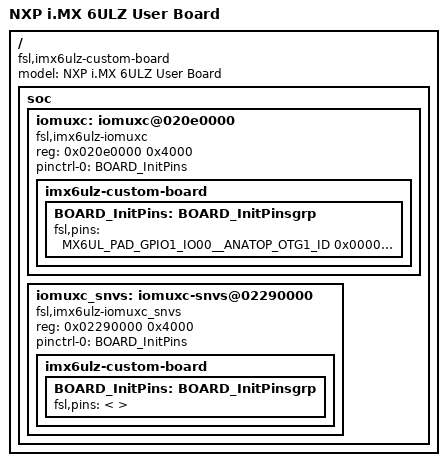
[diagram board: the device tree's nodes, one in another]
/***********************************************************************************************************************
 * This file was generated by the MCUXpresso Config Tools. Any manual edits made to this file
 * will be overwritten if the respective MCUXpresso Config Tools is used to update this file.
 **********************************************************************************************************************/

/*
 * TEXT BELOW IS USED AS SETTING FOR TOOLS *************************************
!!GlobalInfo
product: Pins v8.0
processor: MCIMX6Z0xxx09
package_id: MCIMX6Z0DVM09
mcu_data: ksdk2_0
processor_version: 8.0.0
 * BE CAREFUL MODIFYING THIS COMMENT - IT IS YAML SETTINGS FOR TOOLS ***********
 */


/dts-v1/;

#include "skeleton.dtsi"
#include "imx6ull-pinfunc.h"

/ {
    model = "NXP i.MX 6ULZ User Board";
    compatible = "fsl,imx6ulz-custom-board", "fsl,imx6ulz";

    soc {
        #address-cells = <1>;
        #size-cells = <1>;

        iomuxc: iomuxc@020e0000 {
            compatible = "fsl,imx6ulz-iomuxc";
            reg = <0x020e0000 0x4000>;
        };

        iomuxc_snvs: iomuxc-snvs@02290000 {
            compatible = "fsl,imx6ulz-iomuxc_snvs";
            reg = <0x02290000 0x4000>;
        };
    };
};

&iomuxc {
    pinctrl-names = "default_iomuxc";
    pinctrl-0 = <&BOARD_InitPins>;


    imx6ulz-custom-board {
        BOARD_InitPins: BOARD_InitPinsgrp {                /*!< Function assigned for the core: Cortex-A7[ca7] */
/*
 * TEXT BELOW IS USED AS SETTING FOR TOOLS *************************************
BOARD_InitPins:
- options: {callFromInitBoot: 'false', coreID: ca7}
- pin_list:
  - {pin_num: B3, peripheral: USDHC1, signal: 'usdhc_data, 0', pin_signal: SD1_DATA0}
  - {pin_num: B2, peripheral: USDHC1, signal: 'usdhc_data, 1', pin_signal: SD1_DATA1}
  - {pin_num: B1, peripheral: USDHC1, signal: 'usdhc_data, 2', pin_signal: SD1_DATA2}
  - {pin_num: A2, peripheral: USDHC1, signal: 'usdhc_data, 3', pin_signal: SD1_DATA3}
  - {pin_num: C2, peripheral: USDHC1, signal: usdhc_cmd, pin_signal: SD1_CMD}
  - {pin_num: C1, peripheral: USDHC1, signal: usdhc_clk, pin_signal: SD1_CLK}
  - {pin_num: J14, peripheral: USDHC1, signal: usdhc_cd_b, pin_signal: UART1_RTS_B}
  - {pin_num: D8, peripheral: USDHC2, signal: usdhc_clk, pin_signal: NAND_RE_B}
  - {pin_num: C8, peripheral: USDHC2, signal: usdhc_cmd, pin_signal: NAND_WE_B}
  - {pin_num: B7, peripheral: USDHC2, signal: 'usdhc_data, 1', pin_signal: NAND_DATA01}
  - {pin_num: D7, peripheral: USDHC2, signal: 'usdhc_data, 0', pin_signal: NAND_DATA00}
  - {pin_num: A7, peripheral: USDHC2, signal: 'usdhc_data, 2', pin_signal: NAND_DATA02}
  - {pin_num: D6, peripheral: USDHC2, signal: 'usdhc_data, 3', pin_signal: NAND_DATA03}
  - {pin_num: K14, peripheral: UART1, signal: uart_tx, pin_signal: UART1_TX_DATA}
  - {pin_num: K16, peripheral: UART1, signal: uart_rx, pin_signal: UART1_RX_DATA}
  - {pin_num: J17, peripheral: UART2, signal: uart_tx, pin_signal: UART2_TX_DATA}
  - {pin_num: J16, peripheral: UART2, signal: uart_rx, pin_signal: UART2_RX_DATA}
  - {pin_num: H14, peripheral: UART2, signal: uart_rts_b, pin_signal: UART2_RTS_B}
  - {pin_num: J15, peripheral: UART2, signal: uart_cts_b, pin_signal: UART2_CTS_B}
  - {pin_num: N17, peripheral: PWM1, signal: pwm_out, pin_signal: GPIO1_IO08}
  - {pin_num: M15, peripheral: PWM2, signal: pwm_out, pin_signal: GPIO1_IO09}
  - {pin_num: M16, peripheral: PWM3, signal: pwm_out, pin_signal: GPIO1_IO04}
  - {pin_num: M17, peripheral: PWM4, signal: pwm_out, pin_signal: GPIO1_IO05}
  - {pin_num: G17, peripheral: I2C1, signal: i2c_scl, pin_signal: UART4_TX_DATA}
  - {pin_num: G16, peripheral: I2C1, signal: i2c_sda, pin_signal: UART4_RX_DATA}
  - {pin_num: E1, peripheral: SAI1, signal: sai_rx_bclk, pin_signal: SD2_DATA03}
  - {pin_num: E3, peripheral: SAI1, signal: sai_mclk, pin_signal: SD2_DATA01}
  - {pin_num: D2, peripheral: SAI1, signal: sai_rx_data, pin_signal: SD2_DATA06}
  - {pin_num: E2, peripheral: SAI1, signal: sai_rx_sync, pin_signal: SD2_DATA02}
  - {pin_num: D3, peripheral: SAI1, signal: sai_tx_bclk, pin_signal: SD2_DATA05}
  - {pin_num: D1, peripheral: SAI1, signal: sai_tx_data, pin_signal: SD2_DATA07}
  - {pin_num: D4, peripheral: SAI1, signal: sai_tx_sync, pin_signal: SD2_DATA04}
  - {pin_num: K13, peripheral: USB, signal: usb_otg1_id, pin_signal: GPIO1_IO00}
  - {pin_num: D17, peripheral: USB, signal: usb_otg2_id, pin_signal: KPP_ROW7}
  - {pin_num: E6, peripheral: QSPI, signal: qspi_a_ss0_b, pin_signal: NAND_DQS}
  - {pin_num: A5, peripheral: QSPI, signal: qspi_a_ss1_b, pin_signal: NAND_DATA07}
  - {pin_num: D5, peripheral: QSPI, signal: qspi_a_sclk, pin_signal: NAND_WP_B}
  - {pin_num: A3, peripheral: QSPI, signal: 'qspi_a_data, 0', pin_signal: NAND_READY_B}
  - {pin_num: C5, peripheral: QSPI, signal: 'qspi_a_data, 1', pin_signal: NAND_CE0_B}
  - {pin_num: B5, peripheral: QSPI, signal: 'qspi_a_data, 2', pin_signal: NAND_CE1_B}
  - {pin_num: A4, peripheral: QSPI, signal: 'qspi_a_data, 3', pin_signal: NAND_CLE}
  - {pin_num: B4, peripheral: QSPI, signal: qspi_a_dqs, pin_signal: NAND_ALE}
  - {pin_num: H16, peripheral: UART3, signal: uart_rx, pin_signal: UART3_RX_DATA}
  - {pin_num: H17, peripheral: UART3, signal: uart_tx, pin_signal: UART3_TX_DATA}
  - {pin_num: G14, peripheral: UART3, signal: uart_rts_b, pin_signal: UART3_RTS_B}
  - {pin_num: H15, peripheral: UART3, signal: uart_cts_b, pin_signal: UART3_CTS_B}
  - {pin_num: M15, peripheral: SPDIF, signal: spdif_in, pin_signal: GPIO1_IO09}
  - {pin_num: N17, peripheral: SPDIF, signal: spdif_out, pin_signal: GPIO1_IO08}
  - {pin_num: F17, peripheral: I2C2, signal: i2c_scl, pin_signal: I2C2_SCL}
  - {pin_num: G13, peripheral: I2C2, signal: i2c_sda, pin_signal: I2C2_SDA}
 * BE CAREFUL MODIFYING THIS COMMENT - IT IS YAML SETTINGS FOR TOOLS ***********
 */
            fsl,pins = <
                MX6UL_PAD_GPIO1_IO00__ANATOP_OTG1_ID       0x000010B0
                MX6UL_PAD_GPIO1_IO04__PWM3_OUT             0x000010B0
                MX6UL_PAD_GPIO1_IO05__PWM4_OUT             0x000010B0
                MX6UL_PAD_I2C2_SCL__I2C2_SCL               0x000010B0
                MX6UL_PAD_I2C2_SDA__I2C2_SDA               0x000010B0
                MX6UL_PAD_KPP_ROW7__ANATOP_OTG2_ID         0x000010B0
                MX6UL_PAD_NAND_ALE__QSPI_A_DQS             0x000010B0
                MX6UL_PAD_NAND_CE0_B__QSPI_A_DATA01        0x000010B0
                MX6UL_PAD_NAND_CE1_B__QSPI_A_DATA02        0x000010B0
                MX6UL_PAD_NAND_CLE__QSPI_A_DATA03          0x000010B0
                MX6UL_PAD_NAND_DATA00__USDHC2_DATA0        0x000010B0
                MX6UL_PAD_NAND_DATA01__USDHC2_DATA1        0x000010B0
                MX6UL_PAD_NAND_DATA02__USDHC2_DATA2        0x000010B0
                MX6UL_PAD_NAND_DATA03__USDHC2_DATA3        0x000010B0
                MX6UL_PAD_NAND_DATA07__QSPI_A_SS1_B        0x000010B0
                MX6UL_PAD_NAND_DQS__QSPI_A_SS0_B           0x000010B0
                MX6UL_PAD_NAND_READY_B__QSPI_A_DATA00      0x000010B0
                MX6UL_PAD_NAND_RE_B__USDHC2_CLK            0x000010B0
                MX6UL_PAD_NAND_WE_B__USDHC2_CMD            0x000010B0
                MX6UL_PAD_NAND_WP_B__QSPI_A_SCLK           0x000010B0
                MX6UL_PAD_SD1_CLK__USDHC1_CLK              0x000010B0
                MX6UL_PAD_SD1_CMD__USDHC1_CMD              0x000010B0
                MX6UL_PAD_SD1_DATA0__USDHC1_DATA0          0x000010B0
                MX6UL_PAD_SD1_DATA1__USDHC1_DATA1          0x000010B0
                MX6UL_PAD_SD1_DATA2__USDHC1_DATA2          0x000010B0
                MX6UL_PAD_SD1_DATA3__USDHC1_DATA3          0x000010B0
                MX6UL_PAD_SD2_DATA01__SAI1_MCLK            0x000010B0
                MX6UL_PAD_SD2_DATA02__SAI1_RX_SYNC         0x000010B0
                MX6UL_PAD_SD2_DATA03__SAI1_RX_BCLK         0x000010B0
                MX6UL_PAD_SD2_DATA04__SAI1_TX_SYNC         0x000010B0
                MX6UL_PAD_SD2_DATA05__SAI1_TX_BCLK         0x000010B0
                MX6UL_PAD_SD2_DATA06__SAI1_RX_DATA         0x000010B0
                MX6UL_PAD_SD2_DATA07__SAI1_TX_DATA         0x000010B0
                MX6UL_PAD_UART1_RTS_B__USDHC1_CD_B         0x000010B0
                MX6UL_PAD_UART1_RX_DATA__UART1_DCE_RX      0x000010B0
                MX6UL_PAD_UART1_TX_DATA__UART1_DCE_TX      0x000010B0
                MX6UL_PAD_UART2_CTS_B__UART2_DCE_CTS       0x000010B0
                MX6UL_PAD_UART2_RTS_B__UART2_DCE_RTS       0x000010B0
                MX6UL_PAD_UART2_RX_DATA__UART2_DCE_RX      0x000010B0
                MX6UL_PAD_UART2_TX_DATA__UART2_DCE_TX      0x000010B0
                MX6UL_PAD_UART3_CTS_B__UART3_DCE_CTS       0x000010B0
                MX6UL_PAD_UART3_RTS_B__UART3_DCE_RTS       0x000010B0
                MX6UL_PAD_UART3_RX_DATA__UART3_DCE_RX      0x000010B0
                MX6UL_PAD_UART3_TX_DATA__UART3_DCE_TX      0x000010B0
                MX6UL_PAD_UART4_RX_DATA__I2C1_SDA          0x000010B0
                MX6UL_PAD_UART4_TX_DATA__I2C1_SCL          0x000010B0
            >;
        };
    };
};

&iomuxc_snvs {
    pinctrl-names = "default_iomuxc_snvs";
    pinctrl-0 = <&BOARD_InitPins>;


    imx6ulz-custom-board {
        BOARD_InitPins: BOARD_InitPinsgrp {                /*!< Function assigned for the core: Cortex-A7[ca7] */
/*
 * TEXT BELOW IS USED AS SETTING FOR TOOLS *************************************
BOARD_InitPins:
- options: {callFromInitBoot: 'false', coreID: ca7}
- pin_list:
  - {pin_num: B3, peripheral: USDHC1, signal: 'usdhc_data, 0', pin_signal: SD1_DATA0}
  - {pin_num: B2, peripheral: USDHC1, signal: 'usdhc_data, 1', pin_signal: SD1_DATA1}
  - {pin_num: B1, peripheral: USDHC1, signal: 'usdhc_data, 2', pin_signal: SD1_DATA2}
  - {pin_num: A2, peripheral: USDHC1, signal: 'usdhc_data, 3', pin_signal: SD1_DATA3}
  - {pin_num: C2, peripheral: USDHC1, signal: usdhc_cmd, pin_signal: SD1_CMD}
  - {pin_num: C1, peripheral: USDHC1, signal: usdhc_clk, pin_signal: SD1_CLK}
  - {pin_num: J14, peripheral: USDHC1, signal: usdhc_cd_b, pin_signal: UART1_RTS_B}
  - {pin_num: D8, peripheral: USDHC2, signal: usdhc_clk, pin_signal: NAND_RE_B}
  - {pin_num: C8, peripheral: USDHC2, signal: usdhc_cmd, pin_signal: NAND_WE_B}
  - {pin_num: B7, peripheral: USDHC2, signal: 'usdhc_data, 1', pin_signal: NAND_DATA01}
  - {pin_num: D7, peripheral: USDHC2, signal: 'usdhc_data, 0', pin_signal: NAND_DATA00}
  - {pin_num: A7, peripheral: USDHC2, signal: 'usdhc_data, 2', pin_signal: NAND_DATA02}
  - {pin_num: D6, peripheral: USDHC2, signal: 'usdhc_data, 3', pin_signal: NAND_DATA03}
  - {pin_num: K14, peripheral: UART1, signal: uart_tx, pin_signal: UART1_TX_DATA}
  - {pin_num: K16, peripheral: UART1, signal: uart_rx, pin_signal: UART1_RX_DATA}
  - {pin_num: J17, peripheral: UART2, signal: uart_tx, pin_signal: UART2_TX_DATA}
  - {pin_num: J16, peripheral: UART2, signal: uart_rx, pin_signal: UART2_RX_DATA}
  - {pin_num: H14, peripheral: UART2, signal: uart_rts_b, pin_signal: UART2_RTS_B}
  - {pin_num: J15, peripheral: UART2, signal: uart_cts_b, pin_signal: UART2_CTS_B}
  - {pin_num: N17, peripheral: PWM1, signal: pwm_out, pin_signal: GPIO1_IO08}
  - {pin_num: M15, peripheral: PWM2, signal: pwm_out, pin_signal: GPIO1_IO09}
  - {pin_num: M16, peripheral: PWM3, signal: pwm_out, pin_signal: GPIO1_IO04}
  - {pin_num: M17, peripheral: PWM4, signal: pwm_out, pin_signal: GPIO1_IO05}
  - {pin_num: G17, peripheral: I2C1, signal: i2c_scl, pin_signal: UART4_TX_DATA}
  - {pin_num: G16, peripheral: I2C1, signal: i2c_sda, pin_signal: UART4_RX_DATA}
  - {pin_num: E1, peripheral: SAI1, signal: sai_rx_bclk, pin_signal: SD2_DATA03}
  - {pin_num: E3, peripheral: SAI1, signal: sai_mclk, pin_signal: SD2_DATA01}
  - {pin_num: D2, peripheral: SAI1, signal: sai_rx_data, pin_signal: SD2_DATA06}
  - {pin_num: E2, peripheral: SAI1, signal: sai_rx_sync, pin_signal: SD2_DATA02}
  - {pin_num: D3, peripheral: SAI1, signal: sai_tx_bclk, pin_signal: SD2_DATA05}
  - {pin_num: D1, peripheral: SAI1, signal: sai_tx_data, pin_signal: SD2_DATA07}
  - {pin_num: D4, peripheral: SAI1, signal: sai_tx_sync, pin_signal: SD2_DATA04}
  - {pin_num: K13, peripheral: USB, signal: usb_otg1_id, pin_signal: GPIO1_IO00}
  - {pin_num: D17, peripheral: USB, signal: usb_otg2_id, pin_signal: KPP_ROW7}
  - {pin_num: E6, peripheral: QSPI, signal: qspi_a_ss0_b, pin_signal: NAND_DQS}
  - {pin_num: A5, peripheral: QSPI, signal: qspi_a_ss1_b, pin_signal: NAND_DATA07}
  - {pin_num: D5, peripheral: QSPI, signal: qspi_a_sclk, pin_signal: NAND_WP_B}
  - {pin_num: A3, peripheral: QSPI, signal: 'qspi_a_data, 0', pin_signal: NAND_READY_B}
  - {pin_num: C5, peripheral: QSPI, signal: 'qspi_a_data, 1', pin_signal: NAND_CE0_B}
  - {pin_num: B5, peripheral: QSPI, signal: 'qspi_a_data, 2', pin_signal: NAND_CE1_B}
  - {pin_num: A4, peripheral: QSPI, signal: 'qspi_a_data, 3', pin_signal: NAND_CLE}
  - {pin_num: B4, peripheral: QSPI, signal: qspi_a_dqs, pin_signal: NAND_ALE}
  - {pin_num: H16, peripheral: UART3, signal: uart_rx, pin_signal: UART3_RX_DATA}
  - {pin_num: H17, peripheral: UART3, signal: uart_tx, pin_signal: UART3_TX_DATA}
  - {pin_num: G14, peripheral: UART3, signal: uart_rts_b, pin_signal: UART3_RTS_B}
  - {pin_num: H15, peripheral: UART3, signal: uart_cts_b, pin_signal: UART3_CTS_B}
  - {pin_num: M15, peripheral: SPDIF, signal: spdif_in, pin_signal: GPIO1_IO09}
  - {pin_num: N17, peripheral: SPDIF, signal: spdif_out, pin_signal: GPIO1_IO08}
  - {pin_num: F17, peripheral: I2C2, signal: i2c_scl, pin_signal: I2C2_SCL}
  - {pin_num: G13, peripheral: I2C2, signal: i2c_sda, pin_signal: I2C2_SDA}
 * BE CAREFUL MODIFYING THIS COMMENT - IT IS YAML SETTINGS FOR TOOLS ***********
 */
            fsl,pins = <
            >;
        };
    };
};

/***********************************************************************************************************************
 * EOF
 **********************************************************************************************************************/
